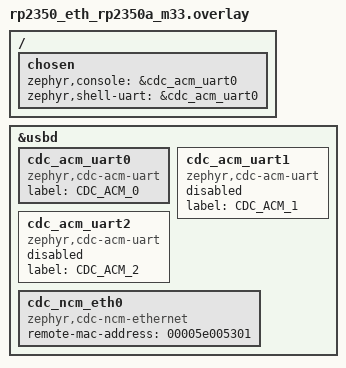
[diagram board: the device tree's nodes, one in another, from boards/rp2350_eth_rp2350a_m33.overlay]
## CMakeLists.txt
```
# SPDX-License-Identifier: Apache-2.0

cmake_minimum_required(VERSION 3.20.0)
find_package(Zephyr REQUIRED HINTS $ENV{ZEPHYR_BASE})
project(sockets_echo_async)

file(GLOB app_sources src/*.c)
target_sources(app PRIVATE ${app_sources})

include(${ZEPHYR_BASE}/samples/net/common/common.cmake)
```

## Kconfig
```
# Copyright (c) 2019 Nordic Semiconductor ASA
# SPDX-License-Identifier: Apache-2.0

menu "Application Configuration"

config APP_BLINKY
	bool "Enable blinky"
	select LED_STRIP
	default n
	help 
	  Use led strip blinky

config APP_RS485 
	bool "Half duplex RS-485 serial"
	select UART_LINE_CTRL
	default n
	help 
		Enable flow control for RS-485 half duplex

config APP_SCPI
	bool "Enable SCPI Console"
	depends on CONSOLE
	depends on CONSOLE_SUBSYS
	depends on UART_CONSOLE
	depends on CONSOLE_GETCHAR
	depends on !CONSOLE_GETLINE
	default n
	help 
	  Enable scpi over console

config APP_FULL_BINDESC
	bool "Enable full bin description fields"
	select BINDESC
	select BINDESC_DEFINE
	select BINDESC_DEFINE_BUILD_TIME
	select BINDESC_BUILD_DATE_TIME_STRING
	select BINDESC_BUILD_TIME_ALWAYS_REBUILD
	select BINDESC_DEFINE_VERSION
	select BINDESC_KERNEL_VERSION_STRING
	select BINDESC_DEFINE_HOST_INFO
	select BINDESC_APP_VERSION_STRING
	select BINDESC_APP_VERSION_MAJOR
	select BINDESC_APP_VERSION_MINOR
	select BINDESC_APP_VERSION_PATCHLEVEL
	select BINDESC_APP_VERSION_NUMBER
	select BINDESC_APP_BUILD_VERSION
	select BINDESC_DEFINE_HOST_INFO
	select BINDESC_HOST_NAME
	select BINDESC_C_COMPILER_NAME
	select BINDESC_C_COMPILER_VERSION
	select BINDESC_CXX_COMPILER_NAME
	select BINDESC_CXX_COMPILER_VERSION
	default y 
	help 
		Selects all default bindesc fields 
		
config SAMPLE_LED_UPDATE_DELAY
	int "Delay between LED updates in ms"
	default 50
	help
	  Delay between LED updates in ms.

config SAMPLE_LED_BRIGHTNESS
	int "LED brightness"
	default 12
	range 1 255
	help
	  Brightness level of each LED. Defaults to a low value to make
	  it easier to distinguish colors.

endmenu

source "Kconfig.zephyr"
```

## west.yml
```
manifest:
  version: 0.8

  projects:
    - name: zephyr
      url: https://github.com/zephyrproject-rtos/zephyr
      revision: v4.3.0
      import:
        file: west.yml
        path-prefix: deps
        name-allowlist:
          - zephyr
          - cmsis
          - cmsis_6
          - hal_nordic
          - mcuboot
          - zcbor
          - mbedtls
          - modbus
          - hal_rpi_pico
          - picolibc
          - littlefs
          - net-tools

    - name: scpi-parser
      url: https://github.com/snhobbs/scpi-parser
      revision: master # or a specific tag/commit
      path: deps/scpi-parser # local folder inside your Zephyr workspace

  self:
    path: app
```

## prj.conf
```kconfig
CONFIG_APP_BLINKY=y
CONFIG_USB_DEVICE_NETWORK_ECM=y
CONFIG_NET_L2_ETHERNET=y
# General config
CONFIG_REQUIRES_FULL_LIBC=y
CONFIG_MAIN_STACK_SIZE=1200

# Networking config
CONFIG_NETWORKING=y
CONFIG_NET_IPV4=y
CONFIG_NET_IPV6=n
CONFIG_NET_TCP=y
CONFIG_NET_ICMPV4_ACCEPT_BROADCAST=y
CONFIG_NET_SOCKETS=y
CONFIG_ZVFS_POLL_MAX=5


# Network driver config
CONFIG_TEST_RANDOM_GENERATOR=y
# Network address config
CONFIG_NET_CONFIG_SETTINGS=y
CONFIG_NET_CONFIG_NEED_IPV4=y
CONFIG_NET_CONFIG_NEED_IPV6=n
CONFIG_NET_CONFIG_AUTO_INIT=y
CONFIG_NET_CONFIG_MY_IPV4_ADDR="192.0.2.100"
CONFIG_NET_CONFIG_PEER_IPV4_ADDR="192.0.2.20"
#CONFIG_NET_CONFIG_MY_IPV6_ADDR="2001:db8::1"
#CONFIG_NET_CONFIG_PEER_IPV6_ADDR="2001:db8::2"

#######################
# Base Configuration 
#######################

#CONFIG_INIT_STACKS=y
#CONFIG_THREAD_STACK_INFO=y
#CONFIG_THREAD_MONITOR=y
CONFIG_BOOT_BANNER=n
#CONFIG_THREAD_NAME=y
#CONFIG_THREAD_RUNTIME_STATS=y
#CONFIG_THREAD_RUNTIME_STATS_USE_TIMING_FUNCTIONS=y
CONFIG_STATS=y

# POSIX_TIMERS requires an embedded C library while the native USB driver is incompatible with it.
# So let's disable it. Once USB_NATIVE_POSIX supports embedded C libraries this can be removed.
CONFIG_POSIX_TIMERS=n
#CONFIG_POSIX_SYSTEM_INTERFACES=y

CONFIG_GPIO=y
CONFIG_CRC=y 
CONFIG_W1=y 
#CONFIG_SYMTAB=y 
CONFIG_SENSOR=y 
#CONFIG_LED=y 

CONFIG_HWINFO=y
#CONFIG_EEPROM=y
#CONFIG_UUID=y

CONFIG_SIZE_OPTIMIZATIONS_AGGRESSIVE=y
CONFIG_LEGACY_GENERATED_INCLUDE_PATH=y
CONFIG_ASSERT_VERBOSE=y
CONFIG_COMPILER_SAVE_TEMPS=y
CONFIG_OUTPUT_PRINT_MEMORY_USAGE=y
CONFIG_BUILD_OUTPUT_META=y
CONFIG_OUTPUT_STAT=y
CONFIG_OUTPUT_SYMBOLS=y
CONFIG_CLEANUP_INTERMEDIATE_FILES=n
CONFIG_BUILD_OUTPUT_STRIP_PATHS=y
CONFIG_CHECK_INIT_PRIORITIES=y
CONFIG_DEBUG=y

#CONFIG_INSTRUMENTATION=y
#CONFIG_INSTRUMENTATION_MODE_CALLGRAPH=y    # For tracing
#CONFIG_INSTRUMENTATION_MODE_STATISTICAL=y  # For profiling

# Kernel options
CONFIG_MAIN_STACK_SIZE=2048



CONFIG_CONSOLE=y
CONFIG_CONSOLE_SUBSYS=y
CONFIG_UART_CONSOLE=y
CONFIG_CONSOLE_HANDLER=y
CONFIG_CONSOLE_GETCHAR=n
CONFIG_CONSOLE_GETLINE=n
#######################
# CPP Configuration 
#######################
CONFIG_CPP=y
#CONFIG_NEWLIB_LIBC=y      # strongly recommended
CONFIG_GLIBCXX_LIBCPP=y
#CONFIG_CPP_MAIN=y
CONFIG_STD_CPP20=y

#######################
# Logging Configuration 
#######################
CONFIG_LOG=y
CONFIG_LOG_CMDS=y
CONFIG_PRINTK=y
CONFIG_LOG_PRINTK=y
CONFIG_LOG_BACKEND_UART=y
# CONFIG_GPIO_LOG_LEVEL_DBG=y
# CONFIG_SPI_LOG_LEVEL_INF=y
#######################
# USB Configuration 
#######################

#CONFIG_USB_DEVICE_STACK_NEXT=y
#CONFIG_CDC_ACM_SERIAL_INITIALIZE_AT_BOOT=y
 # Raspberry Pi
CONFIG_USB_DEVICE_VID=0x2E8A
CONFIG_USB_DEVICE_PID=0x0009
#CONFIG_USB_DEVICE_DFU_PID
#CONFIG_USB_DEVICE_SN

# Raspberry Pi
#CONFIG_CDC_ACM_SERIAL_VID=0x2E8A
 # Raspberry Pi Pico SDK CDC UART
#CONFIG_CDC_ACM_SERIAL_PID=0x0009
# CONFIG_CDC_ACM_SERIAL_PRODUCT_STRING="CDC UART"
CONFIG_USB_DEVICE_PRODUCT="Zephyr Device Product"
CONFIG_USB_DEVICE_MANUFACTURER="Maskset"
CONFIG_USB_DEVICE_STACK=y
#CONFIG_USB_DEVICE_STACK_NEXT=y

CONFIG_USB_CDC_ACM_LOG_LEVEL_OFF=y
CONFIG_USB_DEVICE_INITIALIZE_AT_BOOT=y

#CONFIG_USBC_TCPC_DRIVER=y
#CONFIG_USBC_PPC_DRIVER=y


#######################
# USB DFU Configuration 
#######################
#CONFIG_USB_DEVICE_DFU_PID=0x000f
#CONFIG_USB_DEVICE_DFU_PID=0xffff
#CONFIG_USB_DFU_PERMANENT_DOWNLOAD=y
#CONFIG_USB_DFU_WILL_DETACH=y
#CONFIG_USB_DFU_REBOOT=y
#CONFIG_USB_DFU_ENABLE_UPLOAD=y

#CONFIG_USB_DEVICE_STACK_NEXT=y
#CONFIG_USBD_DFU=y
#CONFIG_USBD_LOG_LEVEL_WRN=y
#CONFIG_USBD_DFU_LOG_LEVEL_WRN=y
#CONFIG_UDC_DRIVER_LOG_LEVEL_WRN=y
##CONFIG_SAMPLE_USBD_PID=0x0005
#CONFIG_DISK_ACCESS=y
#######################
# Shell Configuration 
#######################
CONFIG_SHELL=y
CONFIG_SHELL_BACKEND_TELNET=y

CONFIG_SHELL_MINIMAL=n 
CONFIG_SHELL_CMDS_SELECT=y
CONFIG_SHELL_START_OBSCURED=n
CONFIG_SHELL_LOG_BACKEND=n
#CONFIG_SHELL_BACKEND_SERIAL_CHECK_DTR=n


# allow separate shell + console UART devices
#CONFIG_SHELL_BACKEND_SERIAL=y
#CONFIG_SHELL_BACKEND_SERIAL_CHECK_DTR=n
#CONFIG_SHELL_BACKEND_SERIAL_INTERRUPT_DRIVEN=y


#CONFIG_ADC_SHELL=y
#CONFIG_GPIO_SHELL=y
CONFIG_KERNEL_SHELL=y
CONFIG_DEVICE_SHELL=y
CONFIG_DATE_SHELL=y

CONFIG_STATS_SHELL=y
#CONFIG_INPUT_SHELL=y

CONFIG_SYMTAB_SHELL=y
#CONFIG_UPDATEHUB_SHELL=y
#CONFIG_HAWKBIT_SHELL=y

#CONFIG_CRC_SHELL=y
#CONFIG_ZTEST_SHELL=y
#CONFIG_PSA_SHELL=y
#CONFIG_MBED_TLS_SHELL=y
CONFIG_ISR_TABLE_SHELL=y
#CONFIG_OPENTHREAD_SHELL=y
#CONFIG_LV_Z_SHELL=y
#CONFIG_POSIX_SHELL=y
#CONFIG_RTC_SHELL=y
#CONFIG_VIDEO_SHELL=y
#CONFIG_I2C_SHELL=y
#CONFIG_I3C_SHELL=y
#CONFIG_CAN_SHELL=y
#CONFIG_W1_SHELL=y
CONFIG_SENSOR_SHELL=y
#CONFIG_USBC_TCPC_SHELL=y
#CONFIG_USBC_PPC_SHELL=y
#CONFIG_SENSOR_SHELL_BATTERY=y
#CONFIG_EDAC_SHELL=y
#CONFIG_DAC_SHELL=y
#CONFIG_WDT_SHELL=y
#CONFIG_PWM_SHELL=y
#CONFIG_LED_SHELL=y
#CONFIG_COMPARATOR_SHELL=y
CONFIG_HWINFO_SHELL=y
#CONFIG_REGULATOR_SHELL=y
#CONFIG_UART_SHELL=y
#CONFIG_EEPROM_SHELL=y
#CONFIG_PCIE_SHELL=y
#CONFIG_FPGA_SHELL=y
#CONFIG_COUNTER_SHELL=y
#CONFIG_PSCI_SHELL=y
#CONFIG_HAPTICS_SHELL=y
#CONFIG_STATS_SHELL=y


#CONFIG_POSIX_ENV_SHELL=y
#CONFIG_POSIX_UNAME_SHELL=y


# Flash
CONFIG_FLASH=y
CONFIG_STREAM_FLASH=y
CONFIG_SETTINGS=y
CONFIG_SETTINGS_NONE=n
CONFIG_SETTINGS_RETENTION=y
CONFIG_SETTINGS_FILE=y
CONFIG_SETTINGS_RUNTIME=y
CONFIG_SETTINGS_SHELL=y

CONFIG_FILE_SYSTEM=y
CONFIG_FILE_SYSTEM_SHELL=y
CONFIG_FILE_SYSTEM_LITTLEFS=y
CONFIG_FILE_SYSTEM_SHELL_TEST_COMMANDS=y
CONFIG_FILE_SYSTEM_SHELL_LS_SIZE=y
CONFIG_FILE_SYSTEM_MKFS=y
CONFIG_FS_LITTLEFS_FMP_DEV=y


CONFIG_HWINFO_SHELL=y
CONFIG_STREAM_FLASH_PROGRESS=n
CONFIG_STREAM_FLASH_INSPECT=y
CONFIG_STREAM_FLASH_ERASE=y

CONFIG_FLASH_MAP=y
CONFIG_FLASH_SHELL=y
CONFIG_FLASH_SHELL_TEST_COMMANDS=y


CONFIG_DEVICE_SHELL=y
CONFIG_DEVMEM_SHELL=y
CONFIG_NET_SHELL=y
CONFIG_APP_VERSION_SHELL=y
CONFIG_SHELL_DEVICE_HELPERS=y
CONFIG_KERNEL_SHELL_PANIC_CMD=y
# USB CDC ECM (Ethernet over USB)

CONFIG_POSIX_API=y
CONFIG_POLL=y
```

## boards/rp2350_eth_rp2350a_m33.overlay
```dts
/ {
	chosen {
		zephyr,console = &cdc_acm_uart0;
		zephyr,shell-uart = &cdc_acm_uart0;
		//zephyr,uart-mcumgr = &cdc_acm_uart2;
	};
};

zephyr_udc0: &usbd {
	//compatible = "raspberrypi,rp-usbd";
	status = "okay";
	cdc_acm_uart0: cdc_acm_uart0 {
		status = "okay";
		compatible = "zephyr,cdc-acm-uart";
		label = "CDC_ACM_0";
	};
	cdc_acm_uart1: cdc_acm_uart1 {
		status = "disabled";
		compatible = "zephyr,cdc-acm-uart";
		label = "CDC_ACM_1";
	};
	cdc_acm_uart2: cdc_acm_uart2 {
		status = "disabled";
		compatible = "zephyr,cdc-acm-uart";
		label = "CDC_ACM_2";
	};
	cdc_ncm_eth0: cdc_ncm_eth0 {
		compatible = "zephyr,cdc-ncm-ethernet";
		remote-mac-address = "00005e005301";
	};
};
```

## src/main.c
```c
/*
 * Copyright (c) 2017 Linaro Limited
 *
 * SPDX-License-Identifier: Apache-2.0
 */

#include <zephyr/console/tty.h>
#include <zephyr/devicetree.h>
#include <zephyr/drivers/uart.h>
#include <zephyr/dsp/print_format.h>
#include <zephyr/kernel.h>
#include <zephyr/rtio/rtio.h>
#include <zephyr/sys/printk.h>
#include <zephyr/sys/util_macro.h>

#include <zephyr/device.h>
#include <zephyr/logging/log.h>

#include <zephyr/device.h>
#include <zephyr/drivers/gpio.h>
#include <zephyr/kernel.h>

#include <errno.h>
#include <stdbool.h>
#include <stdio.h>
#include <stdlib.h>

#include "console_server.h"
#include "led.h"

#define WORKQ_STACK_SIZE 1024
#define WORKQ_PRIORITY K_LOWEST_APPLICATION_THREAD_PRIO

K_THREAD_STACK_DEFINE(workq_stack, WORKQ_STACK_SIZE);
static struct k_work_q workq;

K_WORK_DEFINE(led_work, led_work_handler);

void led_timer_handler(struct k_timer *timer_id) {
  k_work_submit_to_queue(&workq, &led_work);
}

K_TIMER_DEFINE(timer, led_timer_handler, NULL);

void start_led_timer() {
  k_timer_start(&timer, K_MSEC(0), K_MSEC(CONFIG_SAMPLE_LED_UPDATE_DELAY));
}
void run_workqueues_and_timers() {
  k_work_queue_start(&workq, workq_stack, K_THREAD_STACK_SIZEOF(workq_stack),
                     WORKQ_PRIORITY, NULL);
  start_led_timer();
}

int main() {
  run_workqueues_and_timers();
  run_server();
  return 0;
}
```

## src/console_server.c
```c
/*
 * Copyright (c) 2017 Linaro Limited
 *
 * SPDX-License-Identifier: Apache-2.0
 */

#include <zephyr/devicetree.h>
#include <zephyr/drivers/uart.h>
#include <zephyr/dsp/print_format.h>
#include <zephyr/kernel.h>
#include <zephyr/rtio/rtio.h>
#include <zephyr/sys/printk.h>
#include <zephyr/sys/util_macro.h>

#include <zephyr/device.h>
#include <zephyr/logging/log.h>

#include <zephyr/device.h>
#include <zephyr/drivers/gpio.h>
#include <zephyr/kernel.h>

#include <errno.h>
#include <stdbool.h>
#include <stdio.h>
#include <stdlib.h>

#include "console_server.h"

#include <zephyr/kernel.h>
#include <zephyr/net/socket.h>
#include <zephyr/posix/fcntl.h>

/* For Zephyr, keep max number of fd's in sync with max poll() capacity */
#ifdef CONFIG_ZVFS_POLL_MAX
#define NUM_FDS CONFIG_ZVFS_POLL_MAX
#else
#define NUM_FDS 5
#endif

#define BIND_PORT 4242

/* Number of simultaneous client connections will be NUM_FDS be minus 2 */
struct pollfd pollfds[NUM_FDS];
int pollnum;

#define fatal(msg, ...)                                                        \
  {                                                                            \
    printf("Error: " msg "\n", ##__VA_ARGS__);                                 \
    exit(1);                                                                   \
  }

static void setblocking(int fd, bool val) {
  int fl, res;

  fl = fcntl(fd, F_GETFL, 0);
  if (fl == -1) {
    fatal("fcntl(F_GETFL): %d", errno);
  }

  if (val) {
    fl &= ~O_NONBLOCK;
  } else {
    fl |= O_NONBLOCK;
  }

  res = fcntl(fd, F_SETFL, fl);
  if (fl == -1) {
    fatal("fcntl(F_SETFL): %d", errno);
  }
}

int pollfds_add(int fd) {
  int i;
  if (pollnum < NUM_FDS) {
    i = pollnum++;
  } else {
    for (i = 0; i < NUM_FDS; i++) {
      if (pollfds[i].fd < 0) {
        goto found;
      }
    }

    return -1;
  }

found:
  pollfds[i].fd = fd;
  pollfds[i].events = POLLIN;

  return 0;
}

void pollfds_del(int fd) {
  for (int i = 0; i < pollnum; i++) {
    if (pollfds[i].fd == fd) {
      pollfds[i].fd = -1;
      break;
    }
  }
}

int run_server(void) {
  int res;
  static int counter;
  int num_servs = 0;
#if !defined(USE_IPV6) || !(CONFIG_SOC_SERIES_CC32XX)
  int serv4;
  struct sockaddr_in bind_addr4 = {
      .sin_family = AF_INET,
      .sin_port = htons(BIND_PORT),
      .sin_addr =
          {
              .s_addr = htonl(INADDR_ANY),
          },
  };
#endif

  // wait_for_network();

#if !defined(USE_IPV6) || !(CONFIG_SOC_SERIES_CC32XX)
  serv4 = socket(AF_INET, SOCK_STREAM, IPPROTO_TCP);
  if (serv4 < 0) {
    printf("error: socket: %d\n", errno);
    exit(1);
  }

  res = bind(serv4, (struct sockaddr *)&bind_addr4, sizeof(bind_addr4));
  if (res == -1) {
    printf("Cannot bind IPv4, errno: %d\n", errno);
  }
  num_servs++;

  setblocking(serv4, false);
  listen(serv4, 5);
  pollfds_add(serv4);
#endif

  printf("Asynchronous TCP echo server waits for connections on "
         "port %d...\n",
         BIND_PORT);

  while (1) {
    struct sockaddr_storage client_addr;
    socklen_t client_addr_len = sizeof(client_addr);
    char addr_str[32];

    res = poll(pollfds, pollnum, -1);
    if (res == -1) {
      printf("poll error: %d\n", errno);
      continue;
    }

    for (int i = 0; i < pollnum; i++) {
      if (!(pollfds[i].revents & POLLIN)) {
        continue;
      }
      int fd = pollfds[i].fd;
      if (i < num_servs) {
        /* If server socket */
        int client =
            accept(fd, (struct sockaddr *)&client_addr, &client_addr_len);
        void *addr = &((struct sockaddr_in *)&client_addr)->sin_addr;

        if (client < 0) {
          printf("error: accept: %d\n", errno);
          continue;
        }
        inet_ntop(client_addr.ss_family, addr, addr_str, sizeof(addr_str));
        printf("Connection #%d from %s fd=%d\n", counter++, addr_str, client);
        if (pollfds_add(client) < 0) {
          static char msg[] = "Too many connections\n";

          res = send(client, msg, sizeof(msg) - 1, 0);
          if (res < 0) {
            printf("error: send: %d\n", errno);
          }
          close(client);
        } else {
          setblocking(client, false);
        }
      } else {
        char buf[128];
        int len = recv(fd, buf, sizeof(buf), 0);
        if (len <= 0) {
          if (len < 0) {
            printf("error: recv: %d\n", errno);
          }
        error:
          pollfds_del(fd);
          close(fd);
          printf("Connection fd=%d closed\n", fd);
        } else {
          int out_len;
          const char *p;
          /* We implement semi-async server,
           * where reads are async, but writes
           * *can* be sync (blocking). Note that
           * in majority of cases they expected
           * to not block, but to be robust, we
           * handle all possibilities.
           */
          setblocking(fd, true);

          for (p = buf; len; len -= out_len) {
            out_len = send(fd, p, len, 0);
            if (out_len < 0) {
              printf("error: "
                     "send: %d\n",
                     errno);
              goto error;
            }
            p += out_len;
          }

          setblocking(fd, false);
        }
      }
    }
  }
  return 0;
}
```

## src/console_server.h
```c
#include <zephyr/console/console.h>
#include <zephyr/devicetree.h>
#include <zephyr/drivers/uart.h>
#include <zephyr/dsp/print_format.h>
#include <zephyr/kernel.h>
#include <zephyr/rtio/rtio.h>
#include <zephyr/sys/printk.h>
#include <zephyr/sys/util_macro.h>

#include <zephyr/device.h>
#include <zephyr/logging/log.h>

#include <zephyr/device.h>
#include <zephyr/drivers/gpio.h>
#include <zephyr/kernel.h>

#ifdef __cplusplus
extern "C" {
#endif
extern int run_server();
#ifdef __cplusplus
};
#endif
```

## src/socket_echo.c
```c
/*
 * Copyright (c) 2017 Linaro Limited
 *
 * SPDX-License-Identifier: Apache-2.0
 */

#include <zephyr/console/console.h>
#include <zephyr/console/tty.h>
#include <zephyr/devicetree.h>
#include <zephyr/drivers/uart.h>
#include <zephyr/dsp/print_format.h>
#include <zephyr/kernel.h>
#include <zephyr/rtio/rtio.h>
#include <zephyr/sys/printk.h>
#include <zephyr/sys/util_macro.h>

#include <zephyr/device.h>
#include <zephyr/logging/log.h>

#include <zephyr/device.h>
#include <zephyr/drivers/gpio.h>
#include <zephyr/kernel.h>

#include <errno.h>
#include <stdbool.h>
#include <stdio.h>
#include <stdlib.h>

#include "led.h"
#define WORKQ_STACK_SIZE 1024
#define WORKQ_PRIORITY K_LOWEST_APPLICATION_THREAD_PRIO

K_THREAD_STACK_DEFINE(workq_stack, WORKQ_STACK_SIZE);
static struct k_work_q workq;

K_WORK_DEFINE(led_work, led_work_handler);

void led_timer_handler(struct k_timer *timer_id) {
  k_work_submit_to_queue(&workq, &led_work);
}

K_TIMER_DEFINE(timer, led_timer_handler, NULL);

void start_led_timer() {
  k_timer_start(&timer, K_MSEC(0), K_MSEC(CONFIG_SAMPLE_LED_UPDATE_DELAY));
}
void run_workqueues_and_timers() {
  k_work_queue_start(&workq, workq_stack, K_THREAD_STACK_SIZEOF(workq_stack),
                     WORKQ_PRIORITY, NULL);
  start_led_timer();
}

#if 1
#if !defined(__ZEPHYR__)

#include <arpa/inet.h>
#include <fcntl.h>
#include <netinet/in.h>
#include <poll.h>
#include <sys/socket.h>
#include <unistd.h>

#define USE_IPV6

#else

#include <zephyr/kernel.h>
#include <zephyr/net/socket.h>
#include <zephyr/posix/fcntl.h>

#include "net_sample_common.h"

#ifdef CONFIG_NET_IPV6
#define USE_IPV6
#endif

#endif

/* For Zephyr, keep max number of fd's in sync with max poll() capacity */
#ifdef CONFIG_ZVFS_POLL_MAX
#define NUM_FDS CONFIG_ZVFS_POLL_MAX
#else
#define NUM_FDS 5
#endif

#define BIND_PORT 4242

/* Number of simultaneous client connections will be NUM_FDS be minus 2 */
struct pollfd pollfds[NUM_FDS];
int pollnum;

#define fatal(msg, ...)                                                        \
  {                                                                            \
    printf("Error: " msg "\n", ##__VA_ARGS__);                                 \
    exit(1);                                                                   \
  }

static void setblocking(int fd, bool val) {
  int fl, res;

  fl = fcntl(fd, F_GETFL, 0);
  if (fl == -1) {
    fatal("fcntl(F_GETFL): %d", errno);
  }

  if (val) {
    fl &= ~O_NONBLOCK;
  } else {
    fl |= O_NONBLOCK;
  }

  res = fcntl(fd, F_SETFL, fl);
  if (fl == -1) {
    fatal("fcntl(F_SETFL): %d", errno);
  }
}

int pollfds_add(int fd) {
  int i;
  if (pollnum < NUM_FDS) {
    i = pollnum++;
  } else {
    for (i = 0; i < NUM_FDS; i++) {
      if (pollfds[i].fd < 0) {
        goto found;
      }
    }

    return -1;
  }

found:
  pollfds[i].fd = fd;
  pollfds[i].events = POLLIN;

  return 0;
}

void pollfds_del(int fd) {
  for (int i = 0; i < pollnum; i++) {
    if (pollfds[i].fd == fd) {
      pollfds[i].fd = -1;
      break;
    }
  }
}

int main(void) {
  int res;
  static int counter;
  int num_servs = 0;
#if !defined(USE_IPV6) || !(CONFIG_SOC_SERIES_CC32XX)
  int serv4;
  struct sockaddr_in bind_addr4 = {
      .sin_family = AF_INET,
      .sin_port = htons(BIND_PORT),
      .sin_addr =
          {
              .s_addr = htonl(INADDR_ANY),
          },
  };
#endif
  run_workqueues_and_timers();

  wait_for_network();

#if !defined(USE_IPV6) || !(CONFIG_SOC_SERIES_CC32XX)
  serv4 = socket(AF_INET, SOCK_STREAM, IPPROTO_TCP);
  if (serv4 < 0) {
    printf("error: socket: %d\n", errno);
    exit(1);
  }

  res = bind(serv4, (struct sockaddr *)&bind_addr4, sizeof(bind_addr4));
  if (res == -1) {
    printf("Cannot bind IPv4, errno: %d\n", errno);
  }
  num_servs++;

  setblocking(serv4, false);
  listen(serv4, 5);
  pollfds_add(serv4);
#endif

  printf("Asynchronous TCP echo server waits for connections on "
         "port %d...\n",
         BIND_PORT);

  while (1) {
    struct sockaddr_storage client_addr;
    socklen_t client_addr_len = sizeof(client_addr);
    char addr_str[32];

    res = poll(pollfds, pollnum, -1);
    if (res == -1) {
      printf("poll error: %d\n", errno);
      continue;
    }

    for (int i = 0; i < pollnum; i++) {
      if (!(pollfds[i].revents & POLLIN)) {
        continue;
      }
      int fd = pollfds[i].fd;
      if (i < num_servs) {
        /* If server socket */
        int client =
            accept(fd, (struct sockaddr *)&client_addr, &client_addr_len);
        void *addr = &((struct sockaddr_in *)&client_addr)->sin_addr;

        if (client < 0) {
          printf("error: accept: %d\n", errno);
          continue;
        }
        inet_ntop(client_addr.ss_family, addr, addr_str, sizeof(addr_str));
        printf("Connection #%d from %s fd=%d\n", counter++, addr_str, client);
        if (pollfds_add(client) < 0) {
          static char msg[] = "Too many connections\n";

          res = send(client, msg, sizeof(msg) - 1, 0);
          if (res < 0) {
            printf("error: send: %d\n", errno);
          }
          close(client);
        } else {
          setblocking(client, false);
        }
      } else {
        char buf[128];
        int len = recv(fd, buf, sizeof(buf), 0);
        if (len <= 0) {
          if (len < 0) {
            printf("error: recv: %d\n", errno);
          }
        error:
          pollfds_del(fd);
          close(fd);
          printf("Connection fd=%d closed\n", fd);
        } else {
          int out_len;
          const char *p;
          /* We implement semi-async server,
           * where reads are async, but writes
           * *can* be sync (blocking). Note that
           * in majority of cases they expected
           * to not block, but to be robust, we
           * handle all possibilities.
           */
          setblocking(fd, true);

          for (p = buf; len; len -= out_len) {
            out_len = send(fd, p, len, 0);
            if (out_len < 0) {
              printf("error: "
                     "send: %d\n",
                     errno);
              goto error;
            }
            p += out_len;
          }

          setblocking(fd, false);
        }
      }
    }
  }
  return 0;
}

#else
int main() {
  run_workqueues_and_timers();
  return 0;
}
#endif
```
